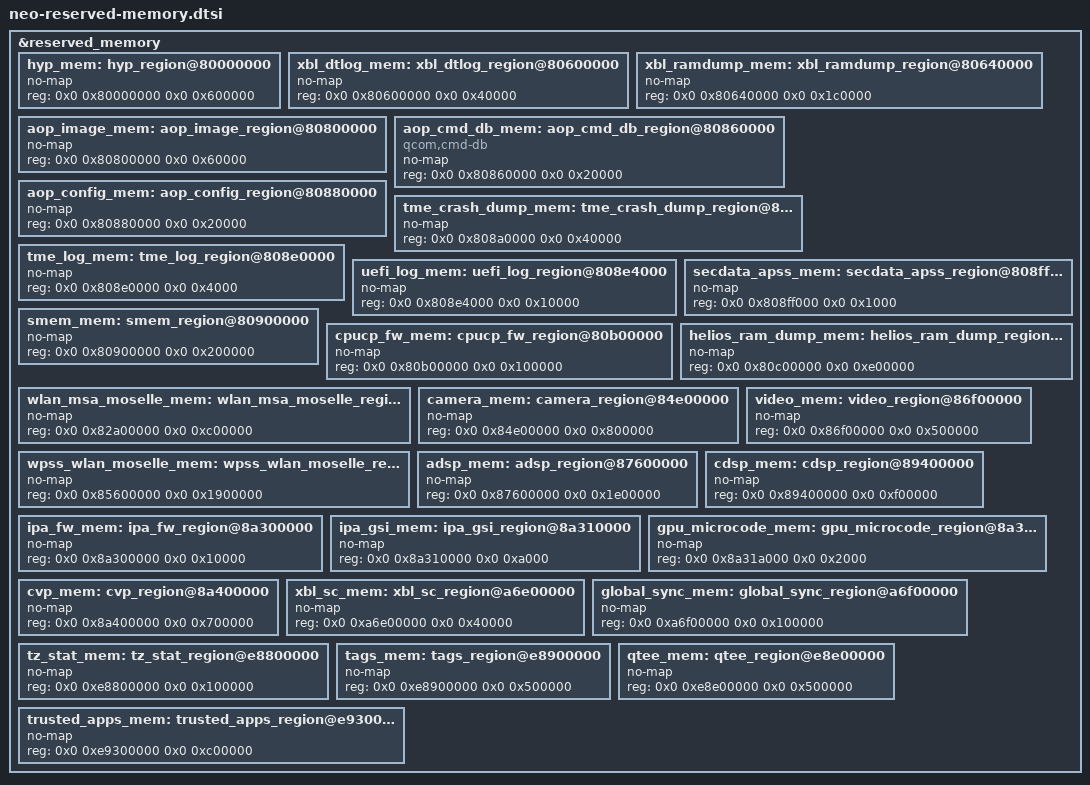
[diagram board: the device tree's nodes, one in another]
&reserved_memory {
	#address-cells = <2>;
	#size-cells = <2>;
	ranges;

	hyp_mem: hyp_region@80000000 {
		no-map;
		reg = <0x0 0x80000000 0x0 0x600000>;
	};

	xbl_dtlog_mem: xbl_dtlog_region@80600000 {
		no-map;
		reg = <0x0 0x80600000 0x0 0x40000>;
	};

	xbl_ramdump_mem: xbl_ramdump_region@80640000 {
		no-map;
		reg = <0x0 0x80640000 0x0 0x1c0000>;
	};

	aop_image_mem: aop_image_region@80800000 {
		no-map;
		reg = <0x0 0x80800000 0x0 0x60000>;
	};

	aop_cmd_db_mem: aop_cmd_db_region@80860000 {
		compatible = "qcom,cmd-db";
		no-map;
		reg = <0x0 0x80860000 0x0 0x20000>;
	};

	aop_config_mem: aop_config_region@80880000 {
		no-map;
		reg = <0x0 0x80880000 0x0 0x20000>;
	};

	tme_crash_dump_mem: tme_crash_dump_region@808a0000 {
		no-map;
		reg = <0x0 0x808a0000 0x0 0x40000>;
	};

	tme_log_mem: tme_log_region@808e0000 {
		no-map;
		reg = <0x0 0x808e0000 0x0 0x4000>;
	};

	uefi_log_mem: uefi_log_region@808e4000 {
		no-map;
		reg = <0x0 0x808e4000 0x0 0x10000>;
	};

	secdata_apss_mem: secdata_apss_region@808ff000 {
		no-map;
		reg = <0x0 0x808ff000 0x0 0x1000>;
	};

	smem_mem: smem_region@80900000 {
		no-map;
		reg = <0x0 0x80900000 0x0 0x200000>;
	};

	cpucp_fw_mem: cpucp_fw_region@80b00000 {
		no-map;
		reg = <0x0 0x80b00000 0x0 0x100000>;
	};

	helios_ram_dump_mem: helios_ram_dump_region@80c00000 {
		no-map;
		reg = <0x0 0x80c00000 0x0 0xe00000>;
	};

	wlan_msa_moselle_mem: wlan_msa_moselle_region@82a00000 {
		no-map;
		reg = <0x0 0x82a00000 0x0 0xc00000>;
	};

	camera_mem: camera_region@84e00000 {
		no-map;
		reg = <0x0 0x84e00000 0x0 0x800000>;
	};

	wpss_wlan_moselle_mem: wpss_wlan_moselle_region@85600000 {
		no-map;
		reg = <0x0 0x85600000 0x0 0x1900000>;
	};

	video_mem: video_region@86f00000 {
		no-map;
		reg = <0x0 0x86f00000 0x0 0x500000>;
	};

	adsp_mem: adsp_region@87600000 {
		no-map;
		reg = <0x0 0x87600000 0x0 0x1e00000>;
	};

	cdsp_mem: cdsp_region@89400000 {
		no-map;
		reg = <0x0 0x89400000 0x0 0xf00000>;
	};

	ipa_fw_mem: ipa_fw_region@8a300000 {
		no-map;
		reg = <0x0 0x8a300000 0x0 0x10000>;
	};

	ipa_gsi_mem: ipa_gsi_region@8a310000 {
		no-map;
		reg = <0x0 0x8a310000 0x0 0xa000>;
	};

	gpu_microcode_mem: gpu_microcode_region@8a31a000 {
		no-map;
		reg = <0x0 0x8a31a000 0x0 0x2000>;
	};

	cvp_mem: cvp_region@8a400000 {
		no-map;
		reg = <0x0 0x8a400000 0x0 0x700000>;
	};

	xbl_sc_mem: xbl_sc_region@a6e00000 {
		no-map;
		reg = <0x0 0xa6e00000 0x0 0x40000>;
	};

	global_sync_mem: global_sync_region@a6f00000 {
		no-map;
		reg = <0x0 0xa6f00000 0x0 0x100000>;
	};

	tz_stat_mem: tz_stat_region@e8800000 {
		no-map;
		reg = <0x0 0xe8800000 0x0 0x100000>;
	};

	tags_mem: tags_region@e8900000 {
		no-map;
		reg = <0x0 0xe8900000 0x0 0x500000>;
	};

	qtee_mem: qtee_region@e8e00000 {
		no-map;
		reg = <0x0 0xe8e00000 0x0 0x500000>;
	};

	trusted_apps_mem: trusted_apps_region@e9300000 {
		no-map;
		reg = <0x0 0xe9300000 0x0 0xc00000>;
	};

};
